# SAM9X75D5MN0 device description
Architecture: ARM926EJ-S; Family: SAM9; Series: SAM9X7
Registers are 32-bit, read-write, reset 0x0 unless marked. A register's access mark holds for its fields unless they carry their own. Offsets are from the block's base; [hi:lo] are bit positions; {n}, {i} and the like mark numbered series.

## PMERRLOC — Programmable Multibit ECC Error Location
Instances: PMERRLOC 0xFFFFE600
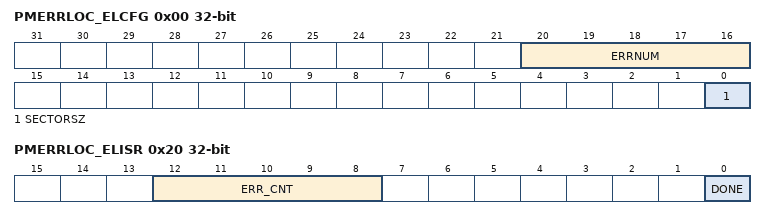
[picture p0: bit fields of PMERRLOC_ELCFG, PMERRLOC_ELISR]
0x00 PMERRLOC_ELCFG — Configuration Register
  [20:16] ERRNUM — Number of Errors
  [0] SECTORSZ — Sector Size
    0=The ECC computation is based on a 512-byte sector; 1=The ECC computation is based on a 1024-byte sector
0x04 PMERRLOC_ELPRIM ro — Primitive Register
  [15:0] PRIMITIV — Primitive Polynomial
0x08 PMERRLOC_ELEN (atomic set of PMERRLOC_ELSR) — Enable Register
  [13:0] ENINIT — Initial Number of Bits in the Codeword
0x0C PMERRLOC_ELDIS (atomic clear of PMERRLOC_ELSR) — Disable Register
  [0] DIS — Disable Error Location Engine
0x10 PMERRLOC_ELSR — Status Register
  [0] BUSY — Error Location Engine Busy
0x14 PMERRLOC_ELIER wo (atomic set of PMERRLOC_ELIMR) — Interrupt Enable Register
  [0] DONE — Computation Terminated Interrupt Enable
0x18 PMERRLOC_ELIDR wo (atomic clear of PMERRLOC_ELIMR) — Interrupt Disable Register
  [0] DONE — Computation Terminated Interrupt Disable
0x1C PMERRLOC_ELIMR ro — Interrupt Mask Register
  [0] DONE — Computation Terminated Interrupt Mask
0x20 PMERRLOC_ELISR ro — Interrupt Status Register
  [12:8] ERR_CNT — Error Counter Value
  [0] DONE — Computation Terminated Interrupt Status
0x28 PMERRLOC_SIGMA0 ro reset 0x1 — SIGMA0 Register
  [13:0] SIGMA — Coefficient of Degree 0 in the SIGMA Polynomial
{0x28+4i} PMERRLOC_SIGMA{i} (i=1..24) — SIGMA{i} Register
  [13:0] SIGMA — Coefficient of Degree x in the SIGMA Polynomial.
{0x8C+4i} PMERRLOC_EL[{i}] (i=0..23) ro — Error Location x Register
  [13:0] ERRLOCN — Error Position within the Set {sector area, spare area}.

## RSTC — Reset Controller
Instances: RSTC 0xFFFFFE00
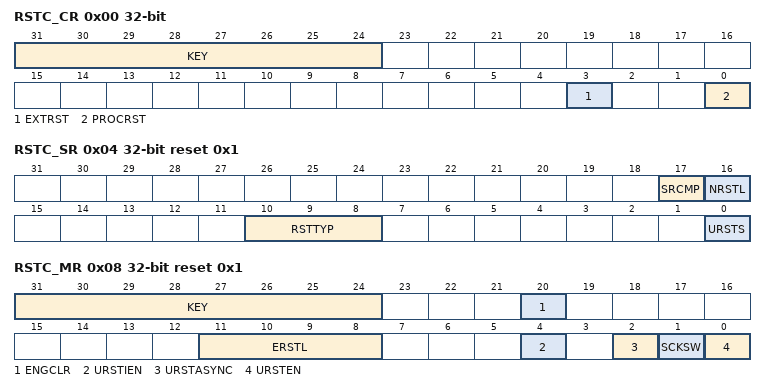
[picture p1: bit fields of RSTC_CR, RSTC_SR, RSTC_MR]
0x00 RSTC_CR wo reset not defined — Control Register
  [31:24] KEY — System Reset Key
    165=PASSWD (Writing any other value in this field aborts the write operation.)
  [3] EXTRST — External Reset
    0=No effect; 1=If KEY = 0xA5, asserts the NRST_OUT pin
  [0] PROCRST — Processor Reset
    0=No effect; 1=If KEY = 0xA5, resets the processor and all the embedded peripherals
0x04 RSTC_SR ro reset 0x1 — Status Register
  [17] SRCMP — Software Reset Command in Progress
    0=No software command is being performed by the RSTC. The RSTC is ready for a software command.; 1=A Software reset command is being performed by the RSTC. The RSTC is busy.
  [16] NRSTL — NRST Pin Level
  [10:8] RSTTYP — Reset Type
    0=GENERAL_RST (First powerup reset); 1=BACKUP_RST (Return from Backup mode); 2=WDT_RST (Watchdog fault occurred); 3=SOFT_RST (Processor reset required by the software); 4=USER_RST (NRST pin detected low); 7=SLCK_XTAL_RST (32.768 kHz crystal failure detection fault occurred)
  [0] URSTS — User Reset Status
    0=No high-to-low edge on NRST happened since the last read of RSTC_SR; 1=At least one high-to-low transition of NRST has been detected since the last read of RSTC_SR
0x08 RSTC_MR reset 0x1 — Mode Register
  [31:24] KEY — Write Access Password
    165=PASSWD (Writing any other value in this field aborts the write operation. Always reads as 0.)
  [20] ENGCLR — Enable GPBR Clear on Tamper Event
    0=Disables the GPBR immediate clear on tamper detection event; 1=Enables the GPBR immediate clear on tamper detection event
  [11:8] ERSTL — External Reset Length
  [4] URSTIEN — User Reset Interrupt Enable
    0=RSTC_SR.USRTS at '1' has no effect on the RSTC interrupt line; 1=RSTC_SR.USRTS at '1' asserts the RSTC interrupt line if URSTEN = 0
  [2] URSTASYNC — User Reset Asynchronous Control
    0=The NRST input signal is managed synchronously; 1=The NRST input signal is managed asynchronously. Note: this mode cannot be selected if the external bus interface drives an SDR/DDR memory device and another memory on the same bus.
  [1] SCKSW — Slow Clock Switching
    0=The detection of a 32.768 kHz crystal failure has no effect; 1=The detection of a 32.768 kHz crystal failure resets the logic supplied by VDDCORE
  [0] URSTEN — User Reset Enable
    0=The detection of a low level on the NRST pin does not generate a User reset; 1=The detection of a low level on the NRST pin triggers a User reset
